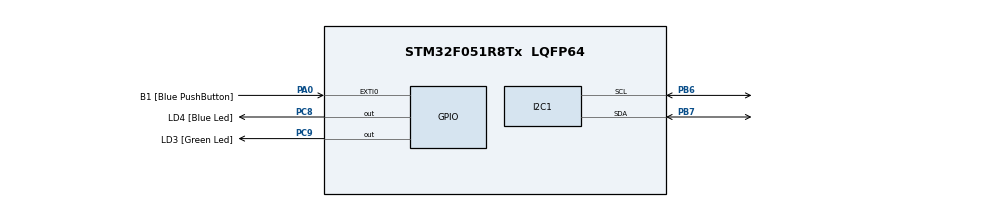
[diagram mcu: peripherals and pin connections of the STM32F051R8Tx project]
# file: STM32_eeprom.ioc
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Mcu.Family=STM32F0
Mcu.Name=STM32F051R8Tx
Mcu.Package=LQFP64
PA0.GPIO_Label=B1 [Blue PushButton]
PA0.GPIO_ModeDefaultEXTI=GPIO_MODE_EVT_RISING
PA0.Signal=GPXTI0
PA13.GPIO_Label=SWDIO
PA13.Signal=SYS_SWDIO
PA14.GPIO_Label=SWCLK
PA14.Signal=SYS_SWCLK
PB6.Mode=I2C
PB6.Signal=I2C1_SCL
PB7.Mode=I2C
PB7.Signal=I2C1_SDA
PC8.GPIO_Label=LD4 [Blue Led]
PC8.Signal=GPIO_Output
PC9.GPIO_Label=LD3 [Green Led]
PC9.Signal=GPIO_Output
ProjectManager.HeapSize=0x200
ProjectManager.StackSize=0x400
ProjectManager.TargetToolchain=Makefile
RCC.AHBFreq_Value=48000000
RCC.APB1Freq_Value=48000000
RCC.APB1TimFreq_Value=48000000
RCC.HCLKFreq_Value=48000000
RCC.PLLMUL=RCC_PLL_MUL12
RCC.SYSCLKFreq_VALUE=48000000
RCC.SYSCLKSource=RCC_SYSCLKSOURCE_PLLCLK
board=STM32F0DISCOVERY

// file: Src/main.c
/* USER CODE BEGIN Header */
/**
  ******************************************************************************
  * @file           : main.c
  * @brief          : Main program body
  ******************************************************************************
  * @attention
  *
  * <h2><center>&copy; Copyright (c) 2019 STMicroelectronics.
  * All rights reserved.</center></h2>
  *
  * This software component is licensed by ST under BSD 3-Clause license,
  * the "License"; You may not use this file except in compliance with the
  * License. You may obtain a copy of the License at:
  *                        opensource.org/licenses/BSD-3-Clause
  *
  ******************************************************************************
  */
/* USER CODE END Header */

#include "main.h"

/* USER CODE BEGIN Includes */
#include "i2c_eeprom.h"
/* USER CODE END Includes */

void SystemClock_Config(void);
static void MX_GPIO_Init(void);
static void MX_I2C1_Init(void);

int main(void)
{

  /* MCU Configuration--------------------------------------------------------*/

  /* Reset of all peripherals, Initializes the Flash interface and the Systick. */

  LL_APB1_GRP2_EnableClock(LL_APB1_GRP2_PERIPH_SYSCFG);
  LL_APB1_GRP1_EnableClock(LL_APB1_GRP1_PERIPH_PWR);

  /* System interrupt init*/

  /* Configure the system clock */
  SystemClock_Config();

  /* Initialize all configured peripherals */
  MX_GPIO_Init();
  MX_I2C1_Init();

  /* USER CODE BEGIN 2 */
#define TOGGLE_GREEN LL_GPIO_TogglePin(LD3_GPIO_Port, LD3_Pin)
#define TOGGLE_BLUE  LL_GPIO_TogglePin(LD4_GPIO_Port, LD4_Pin)

  //TOGGLE_BLUE;
  //TOGGLE_GREEN;

  if(EE_Test() == 0)
	  TOGGLE_GREEN;
  else
	  TOGGLE_BLUE;
  /* USER CODE END 2 */

  /* Infinite loop */
  while (1) {
  }
}

void SystemClock_Config(void)
{
  LL_FLASH_SetLatency(LL_FLASH_LATENCY_1);

  if(LL_FLASH_GetLatency() != LL_FLASH_LATENCY_1)
  {
  Error_Handler();
  }
  LL_RCC_HSI_Enable();

   /* Wait till HSI is ready */
  while(LL_RCC_HSI_IsReady() != 1)
  {

  }
  LL_RCC_HSI_SetCalibTrimming(16);
  LL_RCC_PLL_ConfigDomain_SYS(LL_RCC_PLLSOURCE_HSI_DIV_2, LL_RCC_PLL_MUL_12);
  LL_RCC_PLL_Enable();

   /* Wait till PLL is ready */
  while(LL_RCC_PLL_IsReady() != 1)
  {

  }
  LL_RCC_SetAHBPrescaler(LL_RCC_SYSCLK_DIV_1);
  LL_RCC_SetAPB1Prescaler(LL_RCC_APB1_DIV_1);
  LL_RCC_SetSysClkSource(LL_RCC_SYS_CLKSOURCE_PLL);

   /* Wait till System clock is ready */
  while(LL_RCC_GetSysClkSource() != LL_RCC_SYS_CLKSOURCE_STATUS_PLL)
  {

  }
  LL_Init1msTick(48000000);
  LL_SYSTICK_SetClkSource(LL_SYSTICK_CLKSOURCE_HCLK);
  LL_SetSystemCoreClock(48000000);
  LL_RCC_SetI2CClockSource(LL_RCC_I2C1_CLKSOURCE_HSI);
}

static void MX_I2C1_Init(void)
{

  LL_I2C_InitTypeDef I2C_InitStruct = {0};

  LL_GPIO_InitTypeDef GPIO_InitStruct = {0};

  LL_AHB1_GRP1_EnableClock(LL_AHB1_GRP1_PERIPH_GPIOB);
  /**I2C1 GPIO Configuration
  PB6   ------> I2C1_SCL
  PB7   ------> I2C1_SDA
  */
  GPIO_InitStruct.Pin = LL_GPIO_PIN_6;
  GPIO_InitStruct.Mode = LL_GPIO_MODE_ALTERNATE;
  GPIO_InitStruct.Speed = LL_GPIO_SPEED_FREQ_HIGH;
  GPIO_InitStruct.OutputType = LL_GPIO_OUTPUT_OPENDRAIN;
  GPIO_InitStruct.Pull = LL_GPIO_PULL_UP;
  GPIO_InitStruct.Alternate = LL_GPIO_AF_1;
  LL_GPIO_Init(GPIOB, &GPIO_InitStruct);

  GPIO_InitStruct.Pin = LL_GPIO_PIN_7;
  GPIO_InitStruct.Mode = LL_GPIO_MODE_ALTERNATE;
  GPIO_InitStruct.Speed = LL_GPIO_SPEED_FREQ_HIGH;
  GPIO_InitStruct.OutputType = LL_GPIO_OUTPUT_OPENDRAIN;
  GPIO_InitStruct.Pull = LL_GPIO_PULL_UP;
  GPIO_InitStruct.Alternate = LL_GPIO_AF_1;
  LL_GPIO_Init(GPIOB, &GPIO_InitStruct);

  /* Peripheral clock enable */
  LL_APB1_GRP1_EnableClock(LL_APB1_GRP1_PERIPH_I2C1);

  /** I2C Initialization
  */
  LL_I2C_DisableOwnAddress2(I2C1);
  LL_I2C_DisableGeneralCall(I2C1);
  LL_I2C_EnableClockStretching(I2C1);
  I2C_InitStruct.PeripheralMode = LL_I2C_MODE_I2C;
  I2C_InitStruct.Timing = 0x2000090E;
  I2C_InitStruct.AnalogFilter = LL_I2C_ANALOGFILTER_ENABLE;
  I2C_InitStruct.DigitalFilter = 0;
  I2C_InitStruct.OwnAddress1 = 0;
  I2C_InitStruct.TypeAcknowledge = LL_I2C_ACK;
  I2C_InitStruct.OwnAddrSize = LL_I2C_OWNADDRESS1_7BIT;
  LL_I2C_Init(I2C1, &I2C_InitStruct);
  LL_I2C_EnableAutoEndMode(I2C1);
  LL_I2C_SetOwnAddress2(I2C1, 0, LL_I2C_OWNADDRESS2_NOMASK);

}

static void MX_GPIO_Init(void)
{
  LL_EXTI_InitTypeDef EXTI_InitStruct = {0};
  LL_GPIO_InitTypeDef GPIO_InitStruct = {0};

  /* GPIO Ports Clock Enable */
  LL_AHB1_GRP1_EnableClock(LL_AHB1_GRP1_PERIPH_GPIOA);
  LL_AHB1_GRP1_EnableClock(LL_AHB1_GRP1_PERIPH_GPIOB);
  LL_AHB1_GRP1_EnableClock(LL_AHB1_GRP1_PERIPH_GPIOC);

  /**/
  LL_GPIO_ResetOutputPin(LD4_GPIO_Port, LD4_Pin);

  /**/
  LL_GPIO_ResetOutputPin(LD3_GPIO_Port, LD3_Pin);

  /**/
  LL_SYSCFG_SetEXTISource(LL_SYSCFG_EXTI_PORTA, LL_SYSCFG_EXTI_LINE0);

  /**/
  LL_GPIO_SetPinPull(B1_GPIO_Port, B1_Pin, LL_GPIO_PULL_NO);

  /**/
  LL_GPIO_SetPinMode(B1_GPIO_Port, B1_Pin, LL_GPIO_MODE_INPUT);

  /**/
  EXTI_InitStruct.Line_0_31 = LL_EXTI_LINE_0;
  EXTI_InitStruct.LineCommand = ENABLE;
  EXTI_InitStruct.Mode = LL_EXTI_MODE_EVENT;
  EXTI_InitStruct.Trigger = LL_EXTI_TRIGGER_RISING;
  LL_EXTI_Init(&EXTI_InitStruct);

  /**/
  GPIO_InitStruct.Pin = LD4_Pin;
  GPIO_InitStruct.Mode = LL_GPIO_MODE_OUTPUT;
  GPIO_InitStruct.Speed = LL_GPIO_SPEED_FREQ_LOW;
  GPIO_InitStruct.OutputType = LL_GPIO_OUTPUT_PUSHPULL;
  GPIO_InitStruct.Pull = LL_GPIO_PULL_NO;
  LL_GPIO_Init(LD4_GPIO_Port, &GPIO_InitStruct);

  /**/
  GPIO_InitStruct.Pin = LD3_Pin;
  GPIO_InitStruct.Mode = LL_GPIO_MODE_OUTPUT;
  GPIO_InitStruct.Speed = LL_GPIO_SPEED_FREQ_LOW;
  GPIO_InitStruct.OutputType = LL_GPIO_OUTPUT_PUSHPULL;
  GPIO_InitStruct.Pull = LL_GPIO_PULL_NO;
  LL_GPIO_Init(LD3_GPIO_Port, &GPIO_InitStruct);

}

void Error_Handler(void)
{
}

/************************ (C) COPYRIGHT STMicroelectronics *****END OF FILE****/
